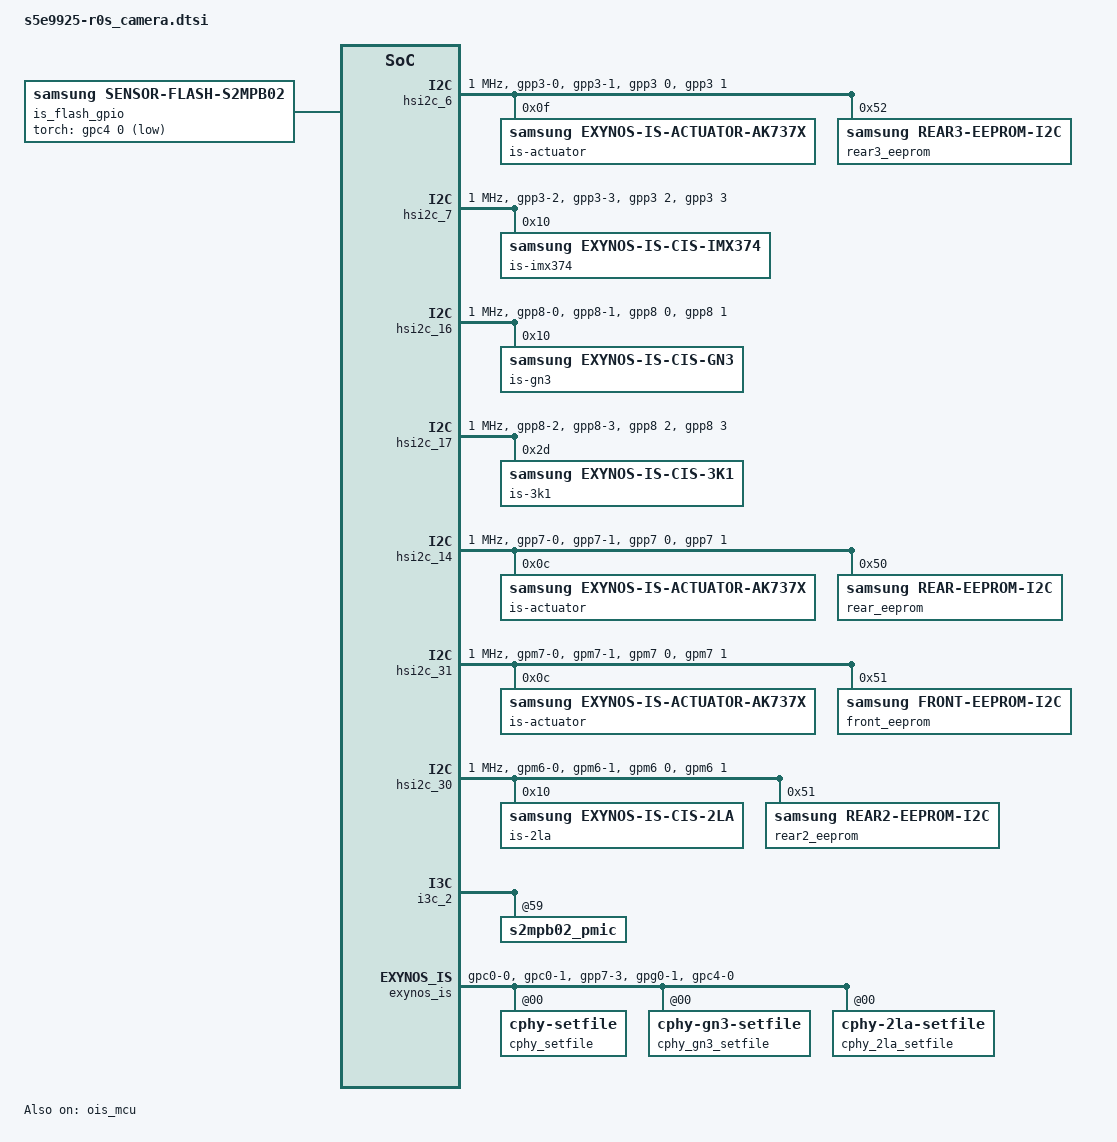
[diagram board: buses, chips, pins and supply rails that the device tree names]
/*
 * Samsung Exynos SoC series Pablo driver
 *
 * Copyright (c) 2020 Samsung Electronics Co., Ltd
 *
 * This program is free software; you can redistribute it and/or modify
 * it under the terms of the GNU General Public License version 2 as
 * published by the Free Software Foundation.
 */

#include <dt-bindings/camera/exynos_is_dt.h>

#include "module_gn3.dtsi"
#include "module_2la.dtsi"
#include "module_3k1.dtsi"
#include "module_imx374.dtsi"

/ {
	fragment@camera {
		target-path = "/";
		__overlay__ {
			#address-cells = <2>;
			#size-cells = <1>;
			interrupt-parent = <&gic>;

			is_flash_gpio: is-flash-gpio@0 {
				compatible = "samsung,sensor-flash-s2mpb02";
				sensor-module = <&is_sensor_gn3>, <&is_sensor_3k1>;
				id = <0 2>;
				status = "okay";

				torch-gpio = <&gpc4 0 0x1>;
			};

			/* OIS_MCU */
			ois_mcu: ois_mcu@173F0000 {
				pinctrl-names = "default";
				pinctrl-0 = <&ois_spi0 &ois_spi1>;
				compatible = "samsung,sensor-ois-mcu";
				reg = <0x0 0x173F0000 0x10000>, /* OIS MCU (SRAM 56KB) */
					<0x0 0x11DD0000 0x10000>, /* I2C: USI05_USI */
					<0x0 0x11DE0000 0x10000>,	/* SPI: USI06_USI */
					<0x0 0x11C30000 0x1000>;	/* PERI setting */
				reg-names = "core", "i2c", "spi", "peri";
				interrupts = <0 INTREQ__OIS_MCU_CSIS IRQ_TYPE_LEVEL_HIGH>;
				id = <0 2>;
				status = "okay";
				mcu_ctrl_actuator = <0 1>;
				mcu_support_photo_fastae;

				power-domains = <&pd_allcsis>;
				clocks = <&clock GATE_OIS_MCU_TOP_QCH>, <&clock DOUT_DIV_CLK_PERIC2_USI06>;
				clock-names = "user_mux", "ipclk_spi";
			};

			/* REAR CAMERA */
			is_sensor0: is_sensor0@17030000 {
				#address-cells = <1>;
				#size-cells = <1>;
				reg = <0x0 0x17050000 0x1000>, /* MIPI-CSI2 */
					<0x0 0x170F0000 0x10000>, /* PHY: M0S4S4S4S4S4S2 */
					<0x0 0x17150050 0x10>; /* CSIS_FRO */
				scenario = <SENSOR_SCENARIO_NORMAL>;	/* Normal, Vision, OIS etc */
				id = <0>;
				csi_ch = <2>;
				status = "okay";
				use_cphy = <1>;

				interrupts = <0 INTREQ__CSIS2 IRQ_TYPE_LEVEL_HIGH>;
				phys = <&mipi_phy_csis2_m0s4s4s4s4s4s4_s22 0>;
				phy_setfile = <&cphy_gn3_setfile>;
				phy_tune_default_mode = "4080 3060 60";
			};

			/* FRONT CAMERA */
			is_sensor1: is_sensor1@17040000 {
				#address-cells = <1>;
				#size-cells = <1>;
				reg = <0x0 0x17030000 0x1000>, /* MIPI-CSI0 */
					<0x0 0x170F0000 0x10000>, /* PHY: M0S4S4S4S4S4S2 */
					<0x0 0x17150050 0x10>; /* CSIS_FRO */
				scenario = <SENSOR_SCENARIO_NORMAL>;    /* Normal, Vision, OIS etc */
				id = <1>;
				csi_ch = <0>;
				status = "okay";
				use_cphy = <0>;

				interrupts = <0 INTREQ__CSIS0 IRQ_TYPE_LEVEL_HIGH>;
				phys = <&mipi_phy_csis0_m0s4s4s4s4s4s4_s22 0>;
			};

			/* Tele CAMERA */
			is_sensor2: is_sensor2@17050000 {
				#address-cells = <1>;
				#size-cells = <1>;
				reg = <0x0 0x17060000 0x1000>, /* MIPI-CSI3 */
					<0x0 0x170F0000 0x10000>, /* PHY: M0S4S4S4S4S4S2 */
					<0x0 0x17150050 0x10>; /* CSIS_FRO */
				scenario = <SENSOR_SCENARIO_NORMAL>;    /* Normal, Vision, OIS etc */
				id = <2>;
				csi_ch = <3>;
				status = "okay";
				use_cphy = <0>;

				interrupts = <0 INTREQ__CSIS3 IRQ_TYPE_LEVEL_HIGH>;
				phys = <&mipi_phy_csis3_m0s4s4s4s4s4s4_s22 0>;
			};

			is_sensor3: is_sensor3@17060000 {
				#address-cells = <1>;
				#size-cells = <1>;
				scenario = <SENSOR_SCENARIO_VISION>;    /* Normal, Vision, OIS etc */
				id = <3>;
				csi_ch = <4>;
				status = "okay";
			};

			/* ULTRA WIDE CAMERA */
			is_sensor4: is_sensor4@17070000 {
				#address-cells = <1>;
				#size-cells = <1>;
				reg = <0x0 0x17040000 0x1000>, /* MIPI-CSI1 */
					<0x0 0x170F0000 0x10000>, /* PHY: M0S4S4S4S4S4S2 */
					<0x0 0x17150050 0x10>; /* CSIS_FRO */
				scenario = <SENSOR_SCENARIO_NORMAL>;    /* Normal, Vision, OIS etc */
				id = <4>;
				csi_ch = <1>;
				status = "okay";
				use_cphy = <1>;

				interrupts = <0 INTREQ__CSIS1 IRQ_TYPE_LEVEL_HIGH>;
				phys = <&mipi_phy_csis1_m0s4s4s4s4s4s4_s22 0>;
				phy_setfile = <&cphy_2la_setfile>;
				phy_tune_default_mode = "2016 1134 120";
			};

			is_sensor5: is_sensor5@17080000 {
				#address-cells = <1>;
				#size-cells = <1>;
				scenario = <SENSOR_SCENARIO_NORMAL>;    /* Normal, Vision, OIS etc */
				id = <1>;
				csi_ch = <1>;
				status = "disabled";
			};
		}; /* end of __overlay__ */
	}; /* end of fragment */
}; /* end of root */

/***** reference symbol node *****/
&pinctrl_5 {
	wide_rst_sleep: wide-rst-sleep {
		samsung,pins = "gpc0-0";
		samsung,pin-con-pdn = <0>;
	};

	uwide_rst_sleep: uwide-rst-sleep {
		samsung,pins = "gpc0-1";
		samsung,pin-con-pdn = <0>;
	};
};

&pinctrl_6 {
	/* REAR WIDE */
	hsi2c16_bus_in: hsi2c16-bus-in {
		samsung,pins = "gpp8-0", "gpp8-1";
		samsung,pin-function = <0>;
		samsung,pin-pud = <0>;
		samsung,pin-drv = <0>;
		samsung,pin-pud-pdn = <0>;
	};

	/* REAR WIDE AF */
	hsi2c14_bus_in: hsi2c14-bus-in {
		samsung,pins = "gpp7-0", "gpp7-1";
		samsung,pin-function = <0>;
		samsung,pin-pud = <0>;
		samsung,pin-drv = <0>;
		samsung,pin-pud-pdn = <0>;
	};

	/* REAR TELE */
	hsi2c17_bus_in: hsi2c17-bus-in {
		samsung,pins = "gpp8-2", "gpp8-3";
		samsung,pin-function = <0>;
		samsung,pin-pud = <0>;
		samsung,pin-drv = <0>;
		samsung,pin-pud-pdn = <0>;
	};

	/* TELE RST */
	tele_rst_sleep: tele-rst-sleep {
		samsung,pins = "gpp7-3";
		samsung,pin-con-pdn = <0>;
	};
};

&pinctrl_7 {
	/* Tele AF */
	hsi2c6_bus_in: hsi2c6-bus-in {
		samsung,pins = "gpp3-0", "gpp3-1";
		samsung,pin-function = <0>;
		samsung,pin-pud = <0>;
		samsung,pin-drv = <0>;
		samsung,pin-pud-pdn = <0>;
	};

	/* Front */
	hsi2c7_bus_in: hsi2c7-bus-in {
		samsung,pins = "gpp3-2", "gpp3-3";
		samsung,pin-function = <0>;
		samsung,pin-pud = <0>;
		samsung,pin-drv = <0>;
		samsung,pin-pud-pdn = <0>;
	};

	/* Front RST */
	vt_rst_sleep: vt-rst-sleep {
		samsung,pins = "gpg0-1";
		samsung,pin-con-pdn = <0>;
	};

	/* torch */
	torch_sleep: torch-sleep {
		samsung,pins = "gpc4-0";
		samsung,pin-con-pdn= <3>;
	};

	/* ois spi 0*/
	ois_spi0: ois-spi0 {
		samsung,pins = "gpp6-0", "gpp6-1";
		samsung,pin-function = <0>;
		samsung,pin-pud = <1>;
	};

	/* ois spi 1*/
	ois_spi1: ois-spi1 {
		samsung,pins = "gpp6-2", "gpp6-3";
		samsung,pin-function = <0>;
		samsung,pin-pud = <0>;
		samsung,pin-con-pdn = <2>;
		samsung,pin-pud-pdn = <0>;
	};
};

&pinctrl_1 {
	/* Ultra Wide */
	hsi2c30_bus_in: hsi2c30-bus-in {
		samsung,pins = "gpm6-0", "gpm6-1";
		samsung,pin-function = <0>;
		samsung,pin-pud = <0>;
		samsung,pin-drv = <0>;
	};

	/* Front AF */
	hsi2c31_bus_in: hsi2c31-bus-in {
		samsung,pins = "gpm7-0", "gpm7-1";
		samsung,pin-function = <0>;
		samsung,pin-pud = <0>;
		samsung,pin-drv = <0>;
		samsung,pin-pud-pdn = <0>;
	};

	hsi2c31_bus: hsi2c31-bus {
		samsung,pin-drv = <3>;
	};
};

&hsi2c_6 {
	#address-cells = <1>;
	#size-cells = <0>;
	gpios = <&gpp3 0 0 &gpp3 1 0>;
	status = "okay";
	clock-frequency = <1000000>;
	samsung,reset-before-trans;
	samsung,fast-plus-mode;

	pinctrl-names = "default","on_i2c","off_i2c";
	pinctrl-0 = <&hsi2c6_bus_in>;
	pinctrl-1 = <&hsi2c6_bus>;
	pinctrl-2 = <&hsi2c6_bus_in>;

	is-actuator@0F { /* tele AF */
		compatible = "samsung,exynos-is-actuator-ak737x";
		sensor-module = <&is_sensor_3k1>;
		reg = <0x0F>;
		id = <2>; /* matching is_sensor id */
		/* AK737x: addr 0xF3, data 0x0E */
		vendor_product_id = <0xF3 0x0E 0xF3 0x13 0xF3 0x00>;
		vendor_first_pos = <2000>;  /* 12bits */
		vendor_first_delay = <2000>;
		vendor_soft_landing_seqid = <2>;
		vendor_soft_landing_list = <640 30 64 30>; /* 1st_pos delay 2nd_pos delay */  /* 12bits */
		vendor_use_sleep_mode;
		vendor_use_standby_mode; /* AK7377 with vendor_use_sleep_mode */
	};

	rear3_eeprom@52 { /* tele x3 */
		compatible = "samsung,rear3-eeprom-i2c";
		reg = <0x52>;

		rom_power_position = <2>;
		rom_size = <0x4000>;
		cal_map_es_version = <23>;
		camera_module_es_version = "A";
		/* skip_cal_loading; */

		/* Rainbow_project_R0G0_Rear_Cal_Map_V023_20210520_for_all */
		/* 0 header */
		header_crc_check_list = <0x0000 0x01FB 0x01FC>;
		/* 0 LSI Wide LSC data */
		/* 1 Tele camera */
		/* 2 ATC data */
		crc_check_list = <0x0200 0x15FB 0x15FC
						0x1D00 0x2D2B 0x2D2C
						0x2D30 0x2D5B 0x2D5C
						0x2D60 0x2D9B 0x2D9C
						0x2DA0 0x2E0B 0x2E0C
						0x2E10 0x361B 0x361C
						0x3620 0x367B 0x367C
						0x1D00 0x36DF 0x36FC
						0x3700 0x37FB 0x37FC>;

		/* Master */
		rom_header_version_start_addr = <0x40>;
		rom_header_cal_data_start_addr = <0x200>;
		rom_header_cal_map_ver_start_addr = <0x70>;
		rom_header_isp_setfile_ver_start_addr = <0x74>;
		rom_header_project_name_start_addr = <0x7E>;
		rom_header_module_id_addr = <0xAE>; /* 0xA8 + reserved bytes */
		rom_header_sensor_id_addr = <0xC8>;
		rom_header_mtf_data_addr = <0x182>;
		rom_awb_master_addr = <0x2D60>;
		rom_awb_module_addr = <0x2D84>;
		/* Near Far Mid1 ... Mid7 */
		rom_af_cal_addr = <0x2D40 0x2D34 0x2D38 0x2D3C>;

		/* Dual cal slave 0 - Tele */
		rom_dualcal_slave0_start_addr = <0x2E10>;
		rom_dualcal_slave0_size = <0x080C>; /* 2060 */
		/* x y z sx sy */
		/* range max_err avg_err dll_version prj_name */
		rom_dualcal_slave1_tilt_list = <0x2EC8 0x2ECC 0x2ED0 0x2EEC 0x2EF0
						0x30E2 0x30E6 0x30EA 0x3104 0x30EF>;

		/* sensor ois - xgg ygg xcoef ycoef xsupper ysupper calmark */
		/* sensor2 ois - xgg ygg xcoef ycoef xsupper ysupper calmark */
		/* TO DO */
		rom_ois_list = <0x2E20 0x2E24 0x2E2C 0x2E2E 0x2E48 0x2E4A 0x2E40
				0x3630 0x3634 0x363C 0x363E 0x3658 0x365A 0x3650>;
	};
};

&hsi2c_7 {
	#address-cells = <1>;
	#size-cells = <0>;
	gpios = <&gpp3 2 0 &gpp3 3 0>;
	status = "okay";
	clock-frequency = <1000000>;
	samsung,reset-before-trans;
	samsung,fast-plus-mode;

	pinctrl-names = "default","on_i2c","off_i2c";
	pinctrl-0 = <&hsi2c7_bus_in>;
	pinctrl-1 = <&hsi2c7_bus>;
	pinctrl-2 = <&hsi2c7_bus_in>;

	is-imx374@10 {
		compatible = "samsung,exynos-is-cis-imx374";
		sensor-module = <&is_sensor_imx374>;
		reg = <0x10>; /* 1 bit right shift */
		id = <1>; /* matching is_sensor id */
		setfile = "default";
		rev_reg = <0x0A1E 1 0x40>;
		vendor_use_adaptive_mipi;
	};
};

&hsi2c_16 {
	#address-cells = <1>;
	#size-cells = <0>;
	gpios = <&gpp8 0 0 &gpp8 1 0>;
	status = "okay";
	clock-frequency = <1000000>;
	samsung,reset-before-trans;
	samsung,fast-plus-mode;

	pinctrl-names = "default","on_i2c","off_i2c";
	pinctrl-0 = <&hsi2c16_bus_in>;
	pinctrl-1 = <&hsi2c16_bus>;
	pinctrl-2 = <&hsi2c16_bus_in>;

	is-gn3@10 {
		compatible = "samsung,exynos-is-cis-gn3";
		sensor-module = <&is_sensor_gn3>;
		reg = <0x10>; /* 1 bit right shift */
		id = <0>; /* matching is_sensor id */
		setfile = "default";
		rev_reg = <0x0002 2 0xA301>;
		vendor_use_adaptive_mipi;
	};
};

&hsi2c_17 {
	#address-cells = <1>;
	#size-cells = <0>;
	gpios = <&gpp8 2 0 &gpp8 3 0>;
	status = "okay";
	clock-frequency = <1000000>;
	samsung,reset-before-trans;
	samsung,fast-plus-mode;

	pinctrl-names = "default","on_i2c","off_i2c";
	pinctrl-0 = <&hsi2c17_bus_in>;
	pinctrl-1 = <&hsi2c17_bus>;
	pinctrl-2 = <&hsi2c17_bus_in>;

	is-3k1@2D {
		compatible = "samsung,exynos-is-cis-3k1";
		sensor-module = <&is_sensor_3k1>;
		reg = <0x2D>; /* 1 bit right shift */
		id = <2>; /* matching is_sensor id */
		setfile = "setA";
		rev_reg = <0x0002 2 0xA000>;
		vendor_use_adaptive_mipi;
	};
};

&hsi2c_14 {
	#address-cells = <1>;
	#size-cells = <0>;
	gpios = <&gpp7 0 0 &gpp7 1 0>;
	status = "okay";
	clock-frequency = <1000000>;
	samsung,reset-before-trans;
	samsung,fast-plus-mode;

	pinctrl-names = "default","on_i2c","off_i2c";
	pinctrl-0 = <&hsi2c14_bus_in>;
	pinctrl-1 = <&hsi2c14_bus>;
	pinctrl-2 = <&hsi2c14_bus_in>;

	is-actuator@0C { /* wide AF */
		compatible = "samsung,exynos-is-actuator-ak737x";
		sensor-module = <&is_sensor_gn3>;
		reg = <0x0C>;
		id = <0>; /* matching is_sensor id */
		/* AK737x: addr 0xF3, data 0x0E */
		vendor_product_id = <0xF3 0x0E 0xF3 0x13 0xF3 0x00>;
		vendor_first_pos = <2000>;  /* 12bits */
		vendor_first_delay = <2000>;
		vendor_soft_landing_seqid = <2>;
		vendor_soft_landing_list = <640 30 64 30>; /* 1st_pos delay 2nd_pos delay */  /* 12bits */
		vendor_use_sleep_mode;
		vendor_use_standby_mode; /* AK7377 with vendor_use_sleep_mode */
	};

	rear_eeprom@50 {
		compatible = "samsung,rear-eeprom-i2c";
		reg = <0x50>;
		rom_power_position = <0>;
		rom_size = <0x8000>;
		cal_map_es_version = <23>;
		camera_module_es_version = "A";
		/* skip_cal_loading; */

		/* Rainbow_project_R0G0_Rear_Cal_Map_V023_20210520_for_all */
		/* 0 header */
		header_crc_check_list = <0x0000 0x01FB 0x01FC>;
		/* 0 LSI Wide LSC data */
		/* 1 Wide camera */
		/* 2 ATC data */
		/* 3 Tele camera */
		/* 4 Sensor */
		crc_check_list = <0x0200 0x15FB 0x15FC
						0x1D00 0x2D2B 0x2D2C
						0x2D30 0x2D5B 0x2D5C
						0x2D60 0x2D9B 0x2D9C
						0x2DA0 0x2E0B 0x2E0C
						0x2E10 0x2E6B 0x2E6C
						0x2E70 0x2E9B 0x2E9C
						0x1D00 0x2EDF 0x2EFC
						0x2F00 0x2FFB 0x2FFC
						0x3000 0x4499 0x449A
						0x3000 0x44DF 0x44FC>;

		/* Master */
		rom_header_version_start_addr = <0x50>;
		rom_header_cal_data_start_addr = <0x200>;
		rom_header_cal_map_ver_start_addr = <0x70>;
		rom_header_isp_setfile_ver_start_addr = <0x74>;
		rom_header_project_name_start_addr = <0x7E>;
		rom_header_module_id_addr = <0xAE>; /* 0xA8 + reserved bytes */
		rom_header_sensor_id_addr = <0xB8>;
		rom_header_mtf_data_addr = <0xE0>;
		rom_paf_cal_start_addr = <0x1D00>;
		rom_awb_master_addr = <0x2D60>;
		rom_awb_module_addr = <0x2D84>;
		/* Near Far Mid1 ... Mid7 */
		rom_af_cal_addr = <0x2D40 0x2D34 0x2D38 0x2D3C>;

		/* rom_xtc_cal_endian_check; */
		rom_xtc_cal_data_addr_list = <0x3000 0x4499 0x1>;

 		/* sensor ois - xgg ygg xcoef ycoef xsupper ysupper calmark */
		/* sensor2 ois - xgg ygg xcoef ycoef xsupper ysupper calmark */
		/* TO DO */
		rom_ois_list = <0x2E20 0x2E24 0x2E2C 0x2E2E 0x2E48 0x2E4A 0x2E40
				0x3630 0x3634 0x363C 0x363E 0x3658 0x365A 0x3650>;
	};
};

&hsi2c_31 {
	#address-cells = <1>;
	#size-cells = <0>;
	gpios = <&gpm7 0 0 &gpm7 1 0>;
	status = "okay";
	clock-frequency = <1000000>;
	samsung,reset-before-trans;
	samsung,fast-plus-mode;

	pinctrl-names = "default","on_i2c","off_i2c";
	pinctrl-0 = <&hsi2c31_bus_in>;
	pinctrl-1 = <&hsi2c31_bus>;
	pinctrl-2 = <&hsi2c31_bus_in>;

	is-actuator@0C { /* front AF */
		compatible = "samsung,exynos-is-actuator-ak737x";
		sensor-module = <&is_sensor_imx374>;
		reg = <0x0C>;
		id = <1>; /* matching is_sensor id */
		/* AK737x: addr 0xF3, data 0x0E */
		vendor_product_id = <0xF3 0x0E>;
		vendor_first_pos = <960>;  /* 12bits */
		vendor_first_delay = <2000>;
	};

	front_eeprom@51 {
		compatible = "samsung,front-eeprom-i2c";
		reg = <0x51>;
		rom_power_position = <1>;
		rom_size = <0x4000>;
		cal_map_es_version = <23>;
		camera_module_es_version = "A";
		/*skip_cal_loading;*/
		/* Rainbow_project_R0G0_Front_Cal_Map_V023_20210520_for_all */
		/* 0 header */
		header_crc_check_list = <0x0000 0x015F 0x01FC>;
		/* 0 master */
		crc_check_list = <0x0200 0x1BFB 0x1BFC
			0x2300 0x32FF 0x3300
			0x330C 0x3337 0x3338
			0x333C 0x3367 0x3368
			0x2300 0x33DF 0x33FC>;
		/* Master */
		rom_header_version_start_addr = <0x30>;
		rom_header_cal_data_start_addr = <0x200>;
		rom_header_cal_map_ver_start_addr = <0x50>;
		/* rom_header_isp_setfile_ver_start_addr = <>; */
		rom_header_project_name_start_addr = <0x5C>;
		rom_header_module_id_addr = <0xAE>; /* 0xA8 + reserved bytes */
		rom_header_sensor_id_addr = <0x70>;
		rom_header_mtf_data_addr = <0xE0>;
		rom_paf_cal_start_addr = <0x2300>;
		rom_awb_master_addr = <0x333C>;
		rom_awb_module_addr = <0x3348>;
		/* Near Far Mid1 ... Mid7 */
		rom_af_cal_addr = <0x331C 0x3310>;
	};
};

&hsi2c_30 {
	#address-cells = <1>;
	#size-cells = <0>;
	gpios = <&gpm6 0 0 &gpm6 1 0>;
	status = "okay";
	clock-frequency = <1000000>;
	samsung,reset-before-trans;
	samsung,fast-plus-mode;

	pinctrl-names = "default","on_i2c","off_i2c";
	pinctrl-0 = <&hsi2c30_bus_in>;
	pinctrl-1 = <&hsi2c30_bus>;
	pinctrl-2 = <&hsi2c30_bus_in>;

	is-2la@10 { /* ultrawide */
		compatible = "samsung,exynos-is-cis-2la";
		sensor-module = <&is_sensor_2la>;
		reg = <0x10>; /* 1 bit right shift */
		id = <4>; /* matching fimc_is_sensor id */
		setfile = "setA";
		status = "okay";
		rev_reg = <0x0002 2 0xA202>;
		vendor_use_adaptive_mipi;
	};

	rear2_eeprom@51 { /* Ultra wide eeprom */
		compatible = "samsung,rear2-eeprom-i2c";
		reg = <0x51>;

		rom_power_position = <4>;
		rom_size = <0x4000>;
		cal_map_es_version = <23>;
		camera_module_es_version = "A";
		/* skip_cal_loading; */

		/* Rainbow_project_R0G0_Rear_Cal_Map_V023_20210520_for_all */
		/* 0 header */
		header_crc_check_list = <0x0000 0x00FB 0x00FC>;
		/* 0 master LSC */
		/* 1 master all */
		crc_check_list = <0x0100 0x14FB 0x14FC
			0x2C60 0x2C9B 0x2C9C
			0x2CA0 0x2D0B 0x2D0C
			0x1C00 0x2DDF 0x2DFC>;
		/* Master */
		rom_header_version_start_addr = <0x40>;
		rom_header_cal_data_start_addr = <0x100>;
		rom_header_cal_map_ver_start_addr = <0x50>;
		rom_header_isp_setfile_ver_start_addr = <0x54>;
		rom_header_project_name_start_addr = <0x5E>;
		rom_header_module_id_addr = <0xAE>; /* 0xA8 + reserved bytes */
		rom_header_sensor_id_addr = <0xB8>;
		rom_header_mtf_data_addr = <0x66>;
		rom_awb_master_addr = <0x2C60>;
		rom_awb_module_addr = <0x2C84>;
	};
};

&i3c_2 {
	s2mpb02_pmic@59 {
		torch {
			torch1-gpio = <&gpc4 0 0x1>;

			status = "okay";

			leds1 {
				ledname = "leds-sec1";
				id = <0>;
				brightness = <0xE>; /* adaptive Nx100+50 : 1450mA */
				timeout = <0x7>; /* (N+1)x62.5 : 500ms */
				torch_table_enable = <0>;
			};

			leds2 {
				ledname = "torch-sec1";
				id = <1>;
				brightness = <0xE>; /* Nx20 = 280mA */
				timeout = <0xF>;
				torch_table_enable = <1>;
				torch_table = <3 5 5 6 6 8 8 8 10 10>;
				/* 60mA 100mA 120mA 160mA 200mA */
			};
		};
	};
};

&exynos_is {
	phy_ldos = "AVDD_CSI_0P85", "AVDD_CSI_1P2";

	pinctrl-names = "default";
	pinctrl-0 = <&wide_rst_sleep &uwide_rst_sleep &tele_rst_sleep &vt_rst_sleep &torch_sleep>;

	secure_mem_info = <0x96000000 0x36F0000>;

	vender {
		use_module_check;
		use_ois;
		check_sensor_vendor;
		ois_sensor_index = <0>;
		aperture_sensor_index = <0>;
		mcu_sensor_index = <0>;

		is_vendor_sensor_count = <5>;
		max_supported_camera = <6>;
		supported_cameraId = <56 58 52 1 21 23>;
		ois_gyro_list = <0x00 0x00 0x10 0x00 0x00>;
		/*
		* Wide(0)
		* Front(1)
		* U Wide(2)
		* Front 80(3) - not available for factory
		* Rear ToF(4) - not available for factory
		* Front Secure(5) - not available for factory
		* Dual Zoom(20)
		* Dual Portrait Tele(21) - Main Tele/Sub Wide
		* Dual Portrait Wide(23) - Main Wide/Sub U Wide
		* Tele 2x2(50)
		* Tele 17.9(52)
		* Front_3(53)
		* Tele_2(54)
		* Front_4(55)
		* Rear_Wide(56)
		* Rear_UW(58)
		* REAR ToF(80)
		*/

		/* sysfs camera id */
		max_camera_num = <9>;
		sensor_id { /* sensor position = <sensor_id> */
			0 = <71>;	/* GN3 */
			1 = <126>;	/* IMX374 */
			2 = <70>;	/* 3K1 */
			4 = <53>;	/* 2LA */
		};
		camera_info0 {			/* 0 : sysfs rear */
			internal_id = <0>;	/* 0 : wide */
			isp = <0>;		/* 0 : INT, 1 : EXT, 2 : SOC */
			cal_memory = <2>;	/* 0 : N, 1 : FROM, 2 : EEPROM, 3 : OTP */
			read_version = <0>;	/* 0 : SYSFS, 1 : CAMON */
			core_voltage = <0>;	/* 0 : N, 1 : Y */
			upgrade = <0>;		/* 0 : N, 1 : SYSFS , 2 : CAMON */
			fw_write = <0>;		/* 0 : N, 1 : OS, 2 : SD, 3 : ALL */
			fw_dump = <0>;		/* 0 : N, 1 : Y */
			companion = <0>;	/* 0 : N, 1 : Y */
			ois = <1>;		/* 0 : N, 1 : Y */
			valid = <1>;		/* 0 : INVALID, 1 : VALID */
		};
		camera_info1 {			/* 1 : sysfs front */
			internal_id = <1>;	/* 1 : front master */
			isp = <0>;		/* 0 : INT, 1 : EXT, 2 : SOC */
			cal_memory = <2>;	/* 0 : N, 1 : FROM, 2 : EEPROM, 3 : OTP */
			read_version = <0>;	/* 0 : SYSFS, 1 : CAMON */
			core_voltage = <0>;	/* 0 : N, 1 : Y */
			upgrade = <0>;		/* 0 : N, 1 : SYSFS, 2 : CAMON */
			fw_write = <0>;		/* 0 : N, 1 : OS, 2 : SD, 3 : ALL */
			fw_dump = <0>;		/* 0 : N, 1 : Y */
			companion = <0>;	/* 0 : N, 1 : Y */
			ois = <0>;		/* 0 : N, 1 : Y */
			valid = <1>;		/* 0 : INVALID, 1 : VALID */
		};
		camera_info2 {			/* 2 : sysfs rear2 */
			internal_id = <4>;	/* 4 : ultra wide */
			isp = <0>;		/* 0 : INT, 1 : EXT, 2 : SOC */
			cal_memory = <2>;	/* 0 : N, 1 : FROM, 2 : EEPROM, 3 : OTP */
			read_version = <0>;	/* 0 : SYSFS, 1 : CAMON */
			core_voltage = <0>;	/* 0 : N, 1 : Y */
			upgrade = <0>;		/* 0 : N, 1 : SYSFS, 2 : CAMON */
			fw_write = <0>;		/* 0 : N, 1 : OS, 2 : SD, 3 : ALL */
			fw_dump = <0>;		/* 0 : N, 1 : Y */
			companion = <0>;	/* 0 : N, 1 : Y */
			ois = <0>;		/* 0 : N, 1 : Y */
			valid = <1>;		/* 0 : INVALID, 1 : VALID */
		};
		camera_info3 {			/* 3 : sysfs front2 */
			internal_id = <3>;	/* 3 : front sub */
			isp = <0>;		/* 0 : INT, 1 : EXT, 2 : SOC */
			cal_memory = <2>;	/* 0 : N, 1 : FROM, 2 : EEPROM, 3 : OTP */
			read_version = <0>;	/* 0 : SYSFS, 1 : CAMON */
			core_voltage = <0>;	/* 0 : N, 1 : Y */
			upgrade = <0>;		/* 0 : N, 1 : SYSFS, 2 : CAMON */
			fw_write = <0>;		/* 0 : N, 1 : OS, 2 : SD, 3 : ALL */
			fw_dump = <0>;		/* 0 : N, 1 : Y */
			companion = <0>;	/* 0 : N, 1 : Y */
			ois = <0>;		/* 0 : N, 1 : Y */
			valid = <1>;		/* 0 : INVALID, 1 : VALID */
		};
		camera_info4 {			/* 4 : sysfs rear3 */
			internal_id = <2>;	/* 4 : tele */
			isp = <0>;		/* 0 : INT, 1 : EXT, 2 : SOC */
			cal_memory = <2>;	/* 0 : N, 1 : FROM, 2 : EEPROM, 3 : OTP */
			read_version = <0>;	/* 0 : SYSFS, 1 : CAMON */
			core_voltage = <0>;	/* 0 : N, 1 : Y */
			upgrade = <0>;		/* 0 : N, 1 : SYSFS, 2 : CAMON */
			fw_write = <0>;		/* 0 : N, 1 : OS, 2 : SD, 3 : ALL */
			fw_dump = <0>;		/* 0 : N, 1 : Y */
			companion = <0>;	/* 0 : N, 1 : Y */
			ois = <1>;		/* 0 : N, 1 : Y */
			valid = <1>;		/* 0 : INVALID, 1 : VALID   */
		};
		camera_info5 {			/* 5 : sysfs front3 */
			valid = <0>;		/* 0 : INVALID, 1 : VALID */
		};
		camera_info6 {			/* 6 : sysfs rear4 */
			valid = <0>;		/* 0 : INVALID, 1 : VALID */
		};
		camera_info7 {			/* 7 : sysfs front4 */
			valid = <0>;		/* 0 : INVALID, 1 : VALID */
		};
		camera_info8 {			/* 8 : sysfs rear tof */
			internal_id = <8>;	/* 3 : rear tof */
			isp = <0>;		/* 0 : INT, 1 : EXT, 2 : SOC */
			cal_memory = <2>;	/* 0 : N, 1 : FROM, 2 : EEPROM, 3 : OTP  */
			read_version = <0>;	/* 0 : SYSFS, 1 : CAMON */
			core_voltage = <0>;	/* 0 : N, 1 : Y */
			upgrade = <0>;		/* 0 : N, 1 : SYSFS, 2 : CAMON */
			fw_write = <0>;		/* 0 : N, 1 : OS, 2 : SD, 3 : ALL */
			fw_dump = <0>;		/* 0 : N, 1 : Y */
			companion = <0>;	/* 0 : N, 1 : Y */
			ois = <0>;		/* 0 : N, 1 : Y */
			valid = <1>;		/* 0 : INVALID, 1 : VALID */
		};
	};

	lic_offsets {
		/* 3AA = <setA lic offset0, setA lic offset1, set A trigger context */
		/*		setB lic offset0, setB lic offset1, set B trigger context> */
		/* 4672: 4640x4352 */
		/* 5824: 5804x4352 */
		3AA = <5461 10922 16383 0 5461 10922 16383 0>;
	};

	is_dvfs {
		#define CPU_CL0 "0-3"
		#define CPU_CL1 "4-6"
		#define CPU_CL2 "7"
		#define CPU_CL12 "4-7"

		table0 {
			desc = "dvfs table v0.2";

			default_int_cam = <1>;
			default_cam = <1>;
			default_csis = <1>;
			default_isp = <1>;
			default_mif = <1>;
			default_int = <1>;
			default_cpu = CPU_CL0;

			rear_single_wide_photo_int_cam = <6>;
			rear_single_wide_photo_cam = <6>;
			rear_single_wide_photo_csis = <5>;
			rear_single_wide_photo_isp = <6>;
			rear_single_wide_photo_mif = <6>;
			rear_single_wide_photo_int = <5>;
			rear_single_wide_photo_cpu = CPU_CL0;

			rear_single_wide_photo_full_int_cam = <6>;
			rear_single_wide_photo_full_cam = <6>;
			rear_single_wide_photo_full_csis = <5>;
			rear_single_wide_photo_full_isp = <6>;
			rear_single_wide_photo_full_mif = <3>;
			rear_single_wide_photo_full_int = <5>;
			rear_single_wide_photo_full_cpu = CPU_CL0;

			rear_single_wide_video_fhd30_int_cam = <6>;
			rear_single_wide_video_fhd30_cam = <7>;
			rear_single_wide_video_fhd30_csis = <5>;
			rear_single_wide_video_fhd30_isp = <7>;
			rear_single_wide_video_fhd30_mif = <8>;
			rear_single_wide_video_fhd30_int = <5>;
			rear_single_wide_video_fhd30_cpu = CPU_CL0;

			rear_single_wide_videohdr_int_cam = <6>;
			rear_single_wide_videohdr_cam = <6>;
			rear_single_wide_videohdr_csis = <5>;
			rear_single_wide_videohdr_isp = <7>;
			rear_single_wide_videohdr_mif = <8>;
			rear_single_wide_videohdr_int = <5>;
			rear_single_wide_videohdr_cpu = CPU_CL0;

			rear_single_wide_video_fhd60_int_cam = <6>;
			rear_single_wide_video_fhd60_cam = <6>;
			rear_single_wide_video_fhd60_csis = <5>;
			rear_single_wide_video_fhd60_isp = <6>;
			rear_single_wide_video_fhd60_mif = <7>;
			rear_single_wide_video_fhd60_int = <5>;
			rear_single_wide_video_fhd60_cpu = CPU_CL12;

			rear_single_wide_video_fhd60_hf_int_cam = <6>;
			rear_single_wide_video_fhd60_hf_cam = <6>;
			rear_single_wide_video_fhd60_hf_csis = <5>;
			rear_single_wide_video_fhd60_hf_isp = <6>;
			rear_single_wide_video_fhd60_hf_mif = <7>;
			rear_single_wide_video_fhd60_hf_int = <5>;
			rear_single_wide_video_fhd60_hf_cpu = CPU_CL12;

			rear_single_wide_video_fhd60_supersteady_int_cam = <5>;
			rear_single_wide_video_fhd60_supersteady_cam = <6>;
			rear_single_wide_video_fhd60_supersteady_csis = <5>;
			rear_single_wide_video_fhd60_supersteady_isp = <6>;
			rear_single_wide_video_fhd60_supersteady_mif = <7>;
			rear_single_wide_video_fhd60_supersteady_int = <5>;
			rear_single_wide_video_fhd60_supersteady_cpu = CPU_CL12;

			rear_single_wide_video_fhd60_hf_supersteady_int_cam = <5>;
			rear_single_wide_video_fhd60_hf_supersteady_cam = <6>;
			rear_single_wide_video_fhd60_hf_supersteady_csis = <5>;
			rear_single_wide_video_fhd60_hf_supersteady_isp = <6>;
			rear_single_wide_video_fhd60_hf_supersteady_mif = <7>;
			rear_single_wide_video_fhd60_hf_supersteady_int = <5>;
			rear_single_wide_video_fhd60_hf_supersteady_cpu = CPU_CL12;

			rear_single_wide_video_uhd30_int_cam = <6>;
			rear_single_wide_video_uhd30_cam = <6>;
			rear_single_wide_video_uhd30_csis = <5>;
			rear_single_wide_video_uhd30_isp = <7>;
			rear_single_wide_video_uhd30_mif = <7>;
			rear_single_wide_video_uhd30_int = <4>;
			rear_single_wide_video_uhd30_cpu = CPU_CL0;

			rear_single_wide_video_uhd60_int_cam = <5>;
			rear_single_wide_video_uhd60_cam = <5>;
			rear_single_wide_video_uhd60_csis = <5>;
			rear_single_wide_video_uhd60_isp = <6>;
			rear_single_wide_video_uhd60_mif = <5>;
			rear_single_wide_video_uhd60_int = <3>;
			rear_single_wide_video_uhd60_cpu = CPU_CL12;

			rear_single_wide_video_uhd60_hf_int_cam = <5>;
			rear_single_wide_video_uhd60_hf_cam = <5>;
			rear_single_wide_video_uhd60_hf_csis = <5>;
			rear_single_wide_video_uhd60_hf_isp = <7>;
			rear_single_wide_video_uhd60_hf_mif = <6>;
			rear_single_wide_video_uhd60_hf_int = <3>;
			rear_single_wide_video_uhd60_hf_cpu = CPU_CL12;

			rear_single_wide_video_uhd120_int_cam = <6>;
			rear_single_wide_video_uhd120_cam = <4>;
			rear_single_wide_video_uhd120_csis = <5>;
			rear_single_wide_video_uhd120_isp = <4>;
			rear_single_wide_video_uhd120_mif = <3>;
			rear_single_wide_video_uhd120_int = <2>;
			rear_single_wide_video_uhd120_cpu = CPU_CL12;

			rear_single_wide_capture_int_cam = <3>;
			rear_single_wide_capture_cam = <3>;
			rear_single_wide_capture_csis = <5>;
			rear_single_wide_capture_isp = <3>;
			rear_single_wide_capture_mif = <1>;
			rear_single_wide_capture_int = <5>;
			rear_single_wide_capture_cpu = CPU_CL0;

			rear_single_wide_remosaic_photo_int_cam = <1>;
			rear_single_wide_remosaic_photo_cam = <1>;
			rear_single_wide_remosaic_photo_csis = <1>;
			rear_single_wide_remosaic_photo_isp = <1>;
			rear_single_wide_remosaic_photo_mif = <1>;
			rear_single_wide_remosaic_photo_int = <1>;
			rear_single_wide_remosaic_photo_cpu = CPU_CL0;

			rear_single_wide_remosaic_capture_int_cam = <1>;
			rear_single_wide_remosaic_capture_cam = <1>;
			rear_single_wide_remosaic_capture_csis = <1>;
			rear_single_wide_remosaic_capture_isp = <1>;
			rear_single_wide_remosaic_capture_mif = <1>;
			rear_single_wide_remosaic_capture_int = <1>;
			rear_single_wide_remosaic_capture_cpu = CPU_CL0;

			rear_single_wide_video_fhd120_int_cam = <8>;
			rear_single_wide_video_fhd120_cam = <5>;
			rear_single_wide_video_fhd120_csis = <5>;
			rear_single_wide_video_fhd120_isp = <7>;
			rear_single_wide_video_fhd120_mif = <5>;
			rear_single_wide_video_fhd120_int = <4>;
			rear_single_wide_video_fhd120_cpu = CPU_CL12;

			rear_single_wide_video_fhd240_int_cam = <8>;
			rear_single_wide_video_fhd240_cam = <5>;
			rear_single_wide_video_fhd240_csis = <5>;
			rear_single_wide_video_fhd240_isp = <5>;
			rear_single_wide_video_fhd240_mif = <4>;
			rear_single_wide_video_fhd240_int = <3>;
			rear_single_wide_video_fhd240_cpu = CPU_CL12;

			rear_single_wide_video_fhd480_int_cam = <8>;
			rear_single_wide_video_fhd480_cam = <5>;
			rear_single_wide_video_fhd480_csis = <5>;
			rear_single_wide_video_fhd480_isp = <5>;
			rear_single_wide_video_fhd480_mif = <3>;
			rear_single_wide_video_fhd480_int = <2>;
			rear_single_wide_video_fhd480_cpu = CPU_CL12;

			rear_single_wide_ssm_int_cam = <8>;
			rear_single_wide_ssm_cam = <5>;
			rear_single_wide_ssm_csis = <4>;
			rear_single_wide_ssm_isp = <5>;
			rear_single_wide_ssm_mif = <3>;
			rear_single_wide_ssm_int = <2>;
			rear_single_wide_ssm_hpg = <6>;
			rear_single_wide_ssm_cpu = CPU_CL12;

			rear_single_wide_video_8k24_int_cam = <5>;
			rear_single_wide_video_8k24_cam = <5>;
			rear_single_wide_video_8k24_csis = <5>;
			rear_single_wide_video_8k24_isp = <5>;
			rear_single_wide_video_8k24_mif = <6>;
			rear_single_wide_video_8k24_int = <3>;
			rear_single_wide_video_8k24_cpu = CPU_CL0;

			rear_single_wide_video_8k24_hf_int_cam = <5>;
			rear_single_wide_video_8k24_hf_cam = <5>;
			rear_single_wide_video_8k24_hf_csis = <5>;
			rear_single_wide_video_8k24_hf_isp = <6>;
			rear_single_wide_video_8k24_hf_mif = <7>;
			rear_single_wide_video_8k24_hf_int = <3>;
			rear_single_wide_video_8k24_hf_cpu = CPU_CL0;

			rear_single_wide_video_8k30_int_cam = <4>;
			rear_single_wide_video_8k30_cam = <5>;
			rear_single_wide_video_8k30_csis = <5>;
			rear_single_wide_video_8k30_isp = <5>;
			rear_single_wide_video_8k30_mif = <4>;
			rear_single_wide_video_8k30_int = <2>;
			rear_single_wide_video_8k30_cpu = CPU_CL0;

			rear_single_wide_video_8k30_hf_int_cam = <4>;
			rear_single_wide_video_8k30_hf_cam = <5>;
			rear_single_wide_video_8k30_hf_csis = <5>;
			rear_single_wide_video_8k30_hf_isp = <6>;
			rear_single_wide_video_8k30_hf_mif = <5>;
			rear_single_wide_video_8k30_hf_int = <2>;
			rear_single_wide_video_8k30_hf_cpu = CPU_CL0;

			rear_single_wide_vt_int_cam = <6>;
			rear_single_wide_vt_cam = <7>;
			rear_single_wide_vt_csis = <5>;
			rear_single_wide_vt_isp = <7>;
			rear_single_wide_vt_mif = <8>;
			rear_single_wide_vt_int = <5>;
			rear_single_wide_vt_cpu = CPU_CL0;

			rear_single_ultrawide_photo_int_cam = <6>;
			rear_single_ultrawide_photo_cam = <6>;
			rear_single_ultrawide_photo_csis = <6>;
			rear_single_ultrawide_photo_isp = <6>;
			rear_single_ultrawide_photo_mif = <6>;
			rear_single_ultrawide_photo_int = <5>;
			rear_single_ultrawide_photo_cpu = CPU_CL0;

			rear_single_ultrawide_photo_full_int_cam = <6>;
			rear_single_ultrawide_photo_full_cam = <6>;
			rear_single_ultrawide_photo_full_csis = <6>;
			rear_single_ultrawide_photo_full_isp = <6>;
			rear_single_ultrawide_photo_full_mif = <3>;
			rear_single_ultrawide_photo_full_int = <5>;
			rear_single_ultrawide_photo_full_cpu = CPU_CL0;

			rear_single_ultrawide_video_fhd30_int_cam = <6>;
			rear_single_ultrawide_video_fhd30_cam = <7>;
			rear_single_ultrawide_video_fhd30_csis = <6>;
			rear_single_ultrawide_video_fhd30_isp = <7>;
			rear_single_ultrawide_video_fhd30_mif = <8>;
			rear_single_ultrawide_video_fhd30_int = <5>;
			rear_single_ultrawide_video_fhd30_cpu = CPU_CL0;

			rear_single_ultrawide_video_fhd30_supersteady_int_cam = <6>;
			rear_single_ultrawide_video_fhd30_supersteady_cam = <7>;
			rear_single_ultrawide_video_fhd30_supersteady_csis = <6>;
			rear_single_ultrawide_video_fhd30_supersteady_isp = <7>;
			rear_single_ultrawide_video_fhd30_supersteady_mif = <8>;
			rear_single_ultrawide_video_fhd30_supersteady_int = <5>;
			rear_single_ultrawide_video_fhd30_supersteady_cpu = CPU_CL0;

			rear_single_ultrawide_video_fhd30_hf_supersteady_int_cam = <6>;
			rear_single_ultrawide_video_fhd30_hf_supersteady_cam = <7>;
			rear_single_ultrawide_video_fhd30_hf_supersteady_csis = <6>;
			rear_single_ultrawide_video_fhd30_hf_supersteady_isp = <7>;
			rear_single_ultrawide_video_fhd30_hf_supersteady_mif = <8>;
			rear_single_ultrawide_video_fhd30_hf_supersteady_int = <5>;
			rear_single_ultrawide_video_fhd30_hf_supersteady_cpu = CPU_CL0;

			rear_single_ultrawide_video_fhd60_int_cam = <6>;
			rear_single_ultrawide_video_fhd60_cam = <6>;
			rear_single_ultrawide_video_fhd60_csis = <6>;
			rear_single_ultrawide_video_fhd60_isp = <6>;
			rear_single_ultrawide_video_fhd60_mif = <7>;
			rear_single_ultrawide_video_fhd60_int = <5>;
			rear_single_ultrawide_video_fhd60_cpu = CPU_CL12;

			rear_single_ultrawide_video_fhd60_supersteady_int_cam = <1>;
			rear_single_ultrawide_video_fhd60_supersteady_cam = <1>;
			rear_single_ultrawide_video_fhd60_supersteady_csis = <1>;
			rear_single_ultrawide_video_fhd60_supersteady_isp = <1>;
			rear_single_ultrawide_video_fhd60_supersteady_mif = <1>;
			rear_single_ultrawide_video_fhd60_supersteady_int = <1>;
			rear_single_ultrawide_video_fhd60_supersteady_cpu = CPU_CL12;

			rear_single_ultrawide_video_fhd60_hf_supersteady_int_cam = <1>;
			rear_single_ultrawide_video_fhd60_hf_supersteady_cam = <1>;
			rear_single_ultrawide_video_fhd60_hf_supersteady_csis = <1>;
			rear_single_ultrawide_video_fhd60_hf_supersteady_isp = <1>;
			rear_single_ultrawide_video_fhd60_hf_supersteady_mif = <1>;
			rear_single_ultrawide_video_fhd60_hf_supersteady_int = <1>;
			rear_single_ultrawide_video_fhd60_hf_supersteady_cpu = CPU_CL12;

			rear_single_ultrawide_video_uhd30_int_cam = <6>;
			rear_single_ultrawide_video_uhd30_cam = <6>;
			rear_single_ultrawide_video_uhd30_csis = <6>;
			rear_single_ultrawide_video_uhd30_isp = <7>;
			rear_single_ultrawide_video_uhd30_mif = <7>;
			rear_single_ultrawide_video_uhd30_int = <4>;
			rear_single_ultrawide_video_uhd30_cpu = CPU_CL0;

			rear_single_ultrawide_video_uhd60_int_cam = <5>;
			rear_single_ultrawide_video_uhd60_cam = <5>;
			rear_single_ultrawide_video_uhd60_csis = <6>;
			rear_single_ultrawide_video_uhd60_isp = <6>;
			rear_single_ultrawide_video_uhd60_mif = <5>;
			rear_single_ultrawide_video_uhd60_int = <3>;
			rear_single_ultrawide_video_uhd60_cpu = CPU_CL12;

			rear_single_ultrawide_ssm_int_cam = <1>;
			rear_single_ultrawide_ssm_cam = <1>;
			rear_single_ultrawide_ssm_csis = <1>;
			rear_single_ultrawide_ssm_isp = <1>;
			rear_single_ultrawide_ssm_mif = <1>;
			rear_single_ultrawide_ssm_int = <1>;
			rear_single_ultrawide_ssm_hpg = <6>;
			rear_single_ultrawide_ssm_cpu = CPU_CL12;

			rear_single_ultrawide_capture_int_cam = <3>;
			rear_single_ultrawide_capture_cam = <3>;
			rear_single_ultrawide_capture_csis = <6>;
			rear_single_ultrawide_capture_isp = <3>;
			rear_single_ultrawide_capture_mif = <1>;
			rear_single_ultrawide_capture_int = <5>;
			rear_single_ultrawide_capture_cpu = CPU_CL0;

			rear_single_ultrawide_video_fhd120_int_cam = <8>;
			rear_single_ultrawide_video_fhd120_cam = <5>;
			rear_single_ultrawide_video_fhd120_csis = <5>;
			rear_single_ultrawide_video_fhd120_isp = <7>;
			rear_single_ultrawide_video_fhd120_mif = <5>;
			rear_single_ultrawide_video_fhd120_int = <4>;
			rear_single_ultrawide_video_fhd120_cpu = CPU_CL12;

			rear_single_tele_photo_int_cam = <6>;
			rear_single_tele_photo_cam = <6>;
			rear_single_tele_photo_csis = <6>;
			rear_single_tele_photo_isp = <6>;
			rear_single_tele_photo_mif = <6>;
			rear_single_tele_photo_int = <5>;
			rear_single_tele_photo_cpu = CPU_CL0;

			rear_single_tele_photo_full_int_cam = <6>;
			rear_single_tele_photo_full_cam = <6>;
			rear_single_tele_photo_full_csis = <6>;
			rear_single_tele_photo_full_isp = <6>;
			rear_single_tele_photo_full_mif = <3>;
			rear_single_tele_photo_full_int = <5>;
			rear_single_tele_photo_full_cpu = CPU_CL0;

			rear_single_tele_video_fhd30_int_cam = <6>;
			rear_single_tele_video_fhd30_cam = <7>;
			rear_single_tele_video_fhd30_csis = <6>;
			rear_single_tele_video_fhd30_isp = <7>;
			rear_single_tele_video_fhd30_mif = <8>;
			rear_single_tele_video_fhd30_int = <5>;
			rear_single_tele_video_fhd30_cpu = CPU_CL0;

			rear_single_tele_video_uhd30_int_cam = <6>;
			rear_single_tele_video_uhd30_cam = <6>;
			rear_single_tele_video_uhd30_csis = <6>;
			rear_single_tele_video_uhd30_isp = <7>;
			rear_single_tele_video_uhd30_mif = <7>;
			rear_single_tele_video_uhd30_int = <4>;
			rear_single_tele_video_uhd30_cpu = CPU_CL0;

			rear_single_tele_video_fhd60_int_cam = <6>;
			rear_single_tele_video_fhd60_cam = <6>;
			rear_single_tele_video_fhd60_csis = <6>;
			rear_single_tele_video_fhd60_isp = <6>;
			rear_single_tele_video_fhd60_mif = <7>;
			rear_single_tele_video_fhd60_int = <5>;
			rear_single_tele_video_fhd60_cpu = CPU_CL12;

			rear_single_tele_video_uhd60_int_cam = <5>;
			rear_single_tele_video_uhd60_cam = <5>;
			rear_single_tele_video_uhd60_csis = <6>;
			rear_single_tele_video_uhd60_isp = <6>;
			rear_single_tele_video_uhd60_mif = <5>;
			rear_single_tele_video_uhd60_int = <3>;
			rear_single_tele_video_uhd60_cpu = CPU_CL12;

			rear_single_tele_video_8k24_int_cam = <5>;
			rear_single_tele_video_8k24_cam = <5>;
			rear_single_tele_video_8k24_csis = <6>;
			rear_single_tele_video_8k24_isp = <5>;
			rear_single_tele_video_8k24_mif = <6>;
			rear_single_tele_video_8k24_int = <3>;
			rear_single_tele_video_8k24_cpu = CPU_CL0;

			rear_single_tele_video_8k24_hf_int_cam = <5>;
			rear_single_tele_video_8k24_hf_cam = <5>;
			rear_single_tele_video_8k24_hf_csis = <6>;
			rear_single_tele_video_8k24_hf_isp = <6>;
			rear_single_tele_video_8k24_hf_mif = <7>;
			rear_single_tele_video_8k24_hf_int = <3>;
			rear_single_tele_video_8k24_hf_cpu = CPU_CL0;

			rear_single_tele_video_8k30_int_cam = <4>;
			rear_single_tele_video_8k30_cam = <5>;
			rear_single_tele_video_8k30_csis = <6>;
			rear_single_tele_video_8k30_isp = <5>;
			rear_single_tele_video_8k30_mif = <4>;
			rear_single_tele_video_8k30_int = <2>;
			rear_single_tele_video_8k30_cpu = CPU_CL0;

			rear_single_tele_video_8k30_hf_int_cam = <4>;
			rear_single_tele_video_8k30_hf_cam = <5>;
			rear_single_tele_video_8k30_hf_csis = <6>;
			rear_single_tele_video_8k30_hf_isp = <6>;
			rear_single_tele_video_8k30_hf_mif = <5>;
			rear_single_tele_video_8k30_hf_int = <2>;
			rear_single_tele_video_8k30_hf_cpu = CPU_CL0;

			rear_single_tele_capture_int_cam = <3>;
			rear_single_tele_capture_cam = <3>;
			rear_single_tele_capture_csis = <6>;
			rear_single_tele_capture_isp = <3>;
			rear_single_tele_capture_mif = <1>;
			rear_single_tele_capture_int = <5>;
			rear_single_tele_capture_cpu = CPU_CL0;

			rear_single_tele_remosaic_photo_int_cam = <6>;
			rear_single_tele_remosaic_photo_cam = <6>;
			rear_single_tele_remosaic_photo_csis = <6>;
			rear_single_tele_remosaic_photo_isp = <6>;
			rear_single_tele_remosaic_photo_mif = <6>;
			rear_single_tele_remosaic_photo_int = <5>;
			rear_single_tele_remosaic_photo_cpu = CPU_CL0;

			rear_single_tele_remosaic_capture_int_cam = <3>;
			rear_single_tele_remosaic_capture_cam = <3>;
			rear_single_tele_remosaic_capture_csis = <6>;
			rear_single_tele_remosaic_capture_isp = <3>;
			rear_single_tele_remosaic_capture_mif = <1>;
			rear_single_tele_remosaic_capture_int = <5>;
			rear_single_tele_remosaic_capture_cpu = CPU_CL0;

			rear_dual_wide_tele_photo_int_cam = <6>;
			rear_dual_wide_tele_photo_cam = <1>;
			rear_dual_wide_tele_photo_csis = <5>;
			rear_dual_wide_tele_photo_isp = <1>;
			rear_dual_wide_tele_photo_mif = <6>;
			rear_dual_wide_tele_photo_int = <5>;
			rear_dual_wide_tele_photo_cpu = CPU_CL0;

			rear_dual_wide_tele_video_fhd30_int_cam = <6>;
			rear_dual_wide_tele_video_fhd30_cam = <1>;
			rear_dual_wide_tele_video_fhd30_csis = <5>;
			rear_dual_wide_tele_video_fhd30_isp = <1>;
			rear_dual_wide_tele_video_fhd30_mif = <6>;
			rear_dual_wide_tele_video_fhd30_int = <5>;
			rear_dual_wide_tele_video_fhd30_cpu = CPU_CL0;

			rear_dual_wide_tele_video_uhd30_int_cam = <6>;
			rear_dual_wide_tele_video_uhd30_cam = <1>;
			rear_dual_wide_tele_video_uhd30_csis = <5>;
			rear_dual_wide_tele_video_uhd30_isp = <1>;
			rear_dual_wide_tele_video_uhd30_mif = <5>;
			rear_dual_wide_tele_video_uhd30_int = <4>;
			rear_dual_wide_tele_video_uhd30_cpu = CPU_CL0;

			rear_dual_wide_tele_video_fhd60_int_cam = <6>;
			rear_dual_wide_tele_video_fhd60_cam = <1>;
			rear_dual_wide_tele_video_fhd60_csis = <5>;
			rear_dual_wide_tele_video_fhd60_isp = <1>;
			rear_dual_wide_tele_video_fhd60_mif = <5>;
			rear_dual_wide_tele_video_fhd60_int = <5>;
			rear_dual_wide_tele_video_fhd60_cpu = CPU_CL12;

			rear_dual_wide_tele_video_uhd60_int_cam = <1>;
			rear_dual_wide_tele_video_uhd60_cam = <1>;
			rear_dual_wide_tele_video_uhd60_csis = <1>;
			rear_dual_wide_tele_video_uhd60_isp = <1>;
			rear_dual_wide_tele_video_uhd60_mif = <1>;
			rear_dual_wide_tele_video_uhd60_int = <1>;
			rear_dual_wide_tele_video_uhd60_cpu = CPU_CL12;

			rear_dual_wide_tele_capture_int_cam = <3>;
			rear_dual_wide_tele_capture_cam = <1>;
			rear_dual_wide_tele_capture_csis = <5>;
			rear_dual_wide_tele_capture_isp = <1>;
			rear_dual_wide_tele_capture_mif = <1>;
			rear_dual_wide_tele_capture_int = <5>;
			rear_dual_wide_tele_capture_cpu = CPU_CL0;

			rear_dual_wide_ultrawide_photo_int_cam = <6>;
			rear_dual_wide_ultrawide_photo_cam = <1>;
			rear_dual_wide_ultrawide_photo_csis = <5>;
			rear_dual_wide_ultrawide_photo_isp = <1>;
			rear_dual_wide_ultrawide_photo_mif = <6>;
			rear_dual_wide_ultrawide_photo_int = <5>;
			rear_dual_wide_ultrawide_photo_cpu = CPU_CL0;

			rear_dual_wide_ultrawide_video_fhd30_int_cam = <6>;
			rear_dual_wide_ultrawide_video_fhd30_cam = <1>;
			rear_dual_wide_ultrawide_video_fhd30_csis = <5>;
			rear_dual_wide_ultrawide_video_fhd30_isp = <1>;
			rear_dual_wide_ultrawide_video_fhd30_mif = <6>;
			rear_dual_wide_ultrawide_video_fhd30_int = <5>;
			rear_dual_wide_ultrawide_video_fhd30_cpu = CPU_CL0;

			rear_dual_wide_ultrawide_video_uhd30_int_cam = <6>;
			rear_dual_wide_ultrawide_video_uhd30_cam = <1>;
			rear_dual_wide_ultrawide_video_uhd30_csis = <5>;
			rear_dual_wide_ultrawide_video_uhd30_isp = <1>;
			rear_dual_wide_ultrawide_video_uhd30_mif = <5>;
			rear_dual_wide_ultrawide_video_uhd30_int = <5>;
			rear_dual_wide_ultrawide_video_uhd30_cpu = CPU_CL0;

			rear_dual_wide_ultrawide_video_fhd60_int_cam = <6>;
			rear_dual_wide_ultrawide_video_fhd60_cam = <1>;
			rear_dual_wide_ultrawide_video_fhd60_csis = <5>;
			rear_dual_wide_ultrawide_video_fhd60_isp = <1>;
			rear_dual_wide_ultrawide_video_fhd60_mif = <5>;
			rear_dual_wide_ultrawide_video_fhd60_int = <5>;
			rear_dual_wide_ultrawide_video_fhd60_cpu = CPU_CL12;

			rear_dual_wide_ultrawide_video_uhd60_int_cam = <1>;
			rear_dual_wide_ultrawide_video_uhd60_cam = <1>;
			rear_dual_wide_ultrawide_video_uhd60_csis = <1>;
			rear_dual_wide_ultrawide_video_uhd60_isp = <1>;
			rear_dual_wide_ultrawide_video_uhd60_mif = <1>;
			rear_dual_wide_ultrawide_video_uhd60_int = <1>;
			rear_dual_wide_ultrawide_video_uhd60_cpu = CPU_CL12;

			rear_dual_wide_ultrawide_capture_int_cam = <3>;
			rear_dual_wide_ultrawide_capture_cam = <1>;
			rear_dual_wide_ultrawide_capture_csis = <5>;
			rear_dual_wide_ultrawide_capture_isp = <1>;
			rear_dual_wide_ultrawide_capture_mif = <1>;
			rear_dual_wide_ultrawide_capture_int = <5>;
			rear_dual_wide_ultrawide_capture_cpu = CPU_CL0;

			triple_photo_int_cam = <6>;
			triple_photo_cam = <1>;
			triple_photo_csis = <3>;
			triple_photo_isp = <1>;
			triple_photo_mif = <6>;
			triple_photo_int = <5>;
			triple_photo_cpu = CPU_CL0;

			triple_video_fhd30_int_cam = <6>;
			triple_video_fhd30_cam = <1>;
			triple_video_fhd30_csis = <3>;
			triple_video_fhd30_isp = <1>;
			triple_video_fhd30_mif = <6>;
			triple_video_fhd30_int = <5>;
			triple_video_fhd30_cpu = CPU_CL0;

			triple_video_uhd30_int_cam = <1>;
			triple_video_uhd30_cam = <1>;
			triple_video_uhd30_csis = <1>;
			triple_video_uhd30_isp = <1>;
			triple_video_uhd30_mif = <1>;
			triple_video_uhd30_int = <1>;
			triple_video_uhd30_cpu = CPU_CL0;

			triple_video_fhd60_int_cam = <6>;
			triple_video_fhd60_cam = <1>;
			triple_video_fhd60_csis = <3>;
			triple_video_fhd60_isp = <1>;
			triple_video_fhd60_mif = <5>;
			triple_video_fhd60_int = <5>;
			triple_video_fhd60_cpu = CPU_CL12;

			triple_video_uhd60_int_cam = <1>;
			triple_video_uhd60_cam = <1>;
			triple_video_uhd60_csis = <1>;
			triple_video_uhd60_isp = <1>;
			triple_video_uhd60_mif = <1>;
			triple_video_uhd60_int = <1>;
			triple_video_uhd60_cpu = CPU_CL12;

			triple_capture_int_cam = <3>;
			triple_capture_cam = <1>;
			triple_capture_csis = <3>;
			triple_capture_isp = <1>;
			triple_capture_mif = <1>;
			triple_capture_int = <5>;
			triple_capture_cpu = CPU_CL0;

			front_single_photo_int_cam = <6>;
			front_single_photo_cam = <6>;
			front_single_photo_csis = <6>;
			front_single_photo_isp = <6>;
			front_single_photo_mif = <6>;
			front_single_photo_int = <5>;
			front_single_photo_cpu = CPU_CL0;

			front_single_photo_full_int_cam = <6>;
			front_single_photo_full_cam = <6>;
			front_single_photo_full_csis = <6>;
			front_single_photo_full_isp = <6>;
			front_single_photo_full_mif = <3>;
			front_single_photo_full_int = <5>;
			front_single_photo_full_cpu = CPU_CL0;

			front_single_video_fhd30_int_cam = <6>;
			front_single_video_fhd30_cam = <7>;
			front_single_video_fhd30_csis = <6>;
			front_single_video_fhd30_isp = <7>;
			front_single_video_fhd30_mif = <8>;
			front_single_video_fhd30_int = <5>;
			front_single_video_fhd30_cpu = CPU_CL0;

			front_single_video_uhd30_int_cam = <6>;
			front_single_video_uhd30_cam = <6>;
			front_single_video_uhd30_csis = <6>;
			front_single_video_uhd30_isp = <7>;
			front_single_video_uhd30_mif = <7>;
			front_single_video_uhd30_int = <4>;
			front_single_video_uhd30_cpu = CPU_CL0;

			front_single_video_fhd60_int_cam = <6>;
			front_single_video_fhd60_cam = <6>;
			front_single_video_fhd60_csis = <6>;
			front_single_video_fhd60_isp = <6>;
			front_single_video_fhd60_mif = <7>;
			front_single_video_fhd60_int = <5>;
			front_single_video_fhd60_cpu = CPU_CL12;

			front_single_video_uhd60_int_cam = <5>;
			front_single_video_uhd60_cam = <5>;
			front_single_video_uhd60_csis = <6>;
			front_single_video_uhd60_isp = <6>;
			front_single_video_uhd60_mif = <5>;
			front_single_video_uhd60_int = <3>;
			front_single_video_uhd60_cpu = CPU_CL12;

			front_single_video_uhd120_int_cam = <6>;
			front_single_video_uhd120_cam = <4>;
			front_single_video_uhd120_csis = <6>;
			front_single_video_uhd120_isp = <4>;
			front_single_video_uhd120_mif = <3>;
			front_single_video_uhd120_int = <2>;
			front_single_video_uhd120_cpu = CPU_CL12;

			front_single_capture_int_cam = <3>;
			front_single_capture_cam = <3>;
			front_single_capture_csis = <6>;
			front_single_capture_isp = <3>;
			front_single_capture_mif = <1>;
			front_single_capture_int = <5>;
			front_single_capture_cpu = CPU_CL0;

			front_single_vt_int_cam = <6>;
			front_single_vt_cam = <7>;
			front_single_vt_csis = <6>;
			front_single_vt_isp = <7>;
			front_single_vt_mif = <8>;
			front_single_vt_int = <5>;
			front_single_vt_cpu = CPU_CL0;

			front_single_video_fhd120_int_cam = <6>;
			front_single_video_fhd120_cam = <5>;
			front_single_video_fhd120_csis = <6>;
			front_single_video_fhd120_isp = <7>;
			front_single_video_fhd120_mif = <5>;
			front_single_video_fhd120_int = <4>;
			front_single_video_fhd120_hpg = <8>;
			front_single_video_fhd120_cpu = CPU_CL12;

			rear_single_wide_fastae_int_cam = <1>;
			rear_single_wide_fastae_cam = <1>;            /* VOTF */
			rear_single_wide_fastae_csis = <1>;  /* VOTF */
			rear_single_wide_fastae_isp = <1>;
			rear_single_wide_fastae_mif = <1>;
			rear_single_wide_fastae_int = <1>;
			rear_single_wide_fastae_cpu = CPU_CL0;

			front_single_fastae_int_cam = <1>;
			front_single_fastae_cam = <1>;
			front_single_fastae_csis = <1>;
			front_single_fastae_isp = <1>;
			front_single_fastae_mif = <1>;
			front_single_fastae_int = <1>;
			front_single_fastae_cpu = CPU_CL0;

			pip_dual_photo_int_cam = <6>;
			pip_dual_photo_cam = <5>;
			pip_dual_photo_csis = <5>;
			pip_dual_photo_isp = <7>;
			pip_dual_photo_mif = <6>;
			pip_dual_photo_int = <6>;
			pip_dual_photo_cpu = CPU_CL0;

			pip_dual_capture_int_cam = <3>;
			pip_dual_capture_cam = <1>;
			pip_dual_capture_csis = <5>;
			pip_dual_capture_isp = <1>;
			pip_dual_capture_mif = <1>;
			pip_dual_capture_int = <1>;
			pip_dual_capture_cpu = CPU_CL0;

			pip_dual_video_fhd30_int_cam = <6>;
			pip_dual_video_fhd30_cam = <5>;
			pip_dual_video_fhd30_csis = <5>;
			pip_dual_video_fhd30_isp = <7>;
			pip_dual_video_fhd30_mif = <6>;
			pip_dual_video_fhd30_int = <6>;
			pip_dual_video_fhd30_cpu = CPU_CL0;

			ext_rear_single_int_cam = <1>;
			ext_rear_single_cam = <1>;
			ext_rear_single_csis = <1>;
			ext_rear_single_isp = <1>;
			ext_rear_single_mif = <1>;
			ext_rear_single_int = <1>;
			ext_rear_single_cpu = CPU_CL0;

			ext_front_secure_int_cam = <1>;
			ext_front_secure_cam = <1>;
			ext_front_secure_csis = <1>;
			ext_front_secure_isp = <1>;
			ext_front_secure_mif = <1>;
			ext_front_secure_int = <1>;
			ext_front_secure_cpu = CPU_CL0;

			ext_throttling_int_cam = <6>;
			ext_throttling_cam = <0>;
			ext_throttling_csis = <0>;
			ext_throttling_isp = <0>;
			ext_throttling_mif = <6>;
			ext_throttling_int = <0>;
			ext_throttling_hpg = <0>;
			ext_throttling_cpu = CPU_CL0;

			max_int_cam = <1>;
			max_cam = <1>;
			max_csis = <1>;
			max_isp = <1>;
			max_mif = <1>;
			max_int = <1>;
			max_cpu = CPU_CL0;
		};
	};

	/*
	 * default setfiles for CPHY
	 * <addr, bit_start, bit_width, val, index, max_lane>
	 */
	cphy_setfile: cphy-setfile@00 {
		comm {
		       /* bias */
		       0  = <0x1000 0 32 0x00000010 IDX_BIA_VAL 0>; /* M_BIAS_CON0 */
		       1  = <0x1004 0 32 0x00000110 IDX_BIA_VAL 0>; /* M_BIAS_CON1 */
		       2  = <0x1008 0 32 0x00003223 IDX_BIA_VAL 0>; /* M_BIAS_CON2 */
		       3  = <0x1010 0 32 0x00000240 IDX_BIA_VAL 0>; /* M_BIAS_CON4 */
		       4  = <0x1114 0 32 0x00000500 IDX_BIA_VAL 0>; /* M_PLL_CON5 */
		       5  = <0x1118 0 32 0x00000010 IDX_BIA_VAL 0>; /* M_PLL_CON6 */
		       6  = <0x111C 0 32 0x00003D40 IDX_BIA_VAL 0>; /* M_PLL_CON7 */
		       7  = <0x1120 0 32 0x00001E00 IDX_BIA_VAL 0>; /* M_PLL_CON8 */
		       8  = <0x1124 0 32 0x00001300 IDX_BIA_VAL 0>; /* M_PLL_CON9 */
		};

		lane {
			0  = <0x0004 0 32 0x00003D40 IDX_FIX_VAL 3>; /* SD_GNR_CON1 */
			1  = <0x0008 0 32 0x00000031 IDX_FIX_VAL 3>; /* SD_ANA_CON0 */
			2  = <0x000C 0 32 0x0000B349 IDX_FIX_VAL 3>; /* SD_ANA_CON1 */
			3  = <0x0010 0 32 0x00000005 IDX_FIX_VAL 3>; /* SD_ANA_CON2 */
			4  = <0x0014 0 32 0x00008600 IDX_FIX_VAL 3>; /* SD_ANA_CON3 */
			5  = <0x0018 0 32 0x00004040 IDX_FIX_VAL 3>; /* SD_ANA_CON4 */
			6  = <0x001C 0 32 0x00002200 IDX_FIX_VAL 3>; /* SD_ANA_CON5 */
			7  = <0x0020 0 32 0x00000E08 IDX_FIX_VAL 3>; /* SD_ANA_CON6 */
			8  = <0x0024 0 32 0x00000040 IDX_FIX_VAL 3>; /* SD_ANA_CON7 */
			9  = <0x0030 0  8 0x00000000 IDX_STL_VAL 3>; /* SD_TIME_CON0 */
			10 = <0x0030 8  1 0x00000000 IDX_STL_CLK 3>; /* SD_TIME_CON0 */
			11 = <0x0034 0 32 0x00000034 IDX_FIX_VAL 3>; /* SD_TIME_CON1 */
			12 = <0x005C 0 32 0x00001000 IDX_FIX_VAL 3>; /* SD_CRC_DLY_CON0 */
			13 = <0x0064 0 32 0x00001501 IDX_FIX_VAL 3>; /* SD_CRC_CON1 */
			14 = <0x0068 0 32 0x00000023 IDX_FIX_VAL 3>; /* SD_CRC_CON2 */
			15 = <0x009c 0 32 0x00000080 IDX_FIX_VAL 3>; /* SD_CRC_DLY_CON3 */

			/* Enable should be set at last */
			16 = <0x0000 0 32 0x00000001 IDX_FIX_VAL 3>; /* SD_GNR_CON0 */
		};
	};

	cphy_gn3_setfile: cphy-gn3-setfile@00 {
		comm {
		       /* bias */
		       0  = <0x1000 0 32 0x00000010 IDX_BIA_VAL 0>; /* M_BIAS_CON0 */
		       1  = <0x1004 0 32 0x00000110 IDX_BIA_VAL 0>; /* M_BIAS_CON1 */
		       2  = <0x1008 0 32 0x00003223 IDX_BIA_VAL 0>; /* M_BIAS_CON2 */
		       3  = <0x1010 0 32 0x00000240 IDX_BIA_VAL 0>; /* M_BIAS_CON4 */
		       4  = <0x1114 0 32 0x00000500 IDX_BIA_VAL 0>; /* M_PLL_CON5 */
		       5  = <0x1118 0 32 0x00000010 IDX_BIA_VAL 0>; /* M_PLL_CON6 */
		       6  = <0x111C 0 32 0x00003D40 IDX_BIA_VAL 0>; /* M_PLL_CON7 */
		       7  = <0x1120 0 32 0x00001E00 IDX_BIA_VAL 0>; /* M_PLL_CON8 */
		       8  = <0x1124 0 32 0x00001300 IDX_BIA_VAL 0>; /* M_PLL_CON9 */
		};

		lane {
			0  = <0x0004 0 32 0x00003D40 IDX_FIX_VAL 3>; /* SD_GNR_CON1 */
			1  = <0x0008 0 32 0x000000F3 IDX_FIX_VAL 3>; /* SD_ANA_CON0 */
			2  = <0x000C 0 32 0x0000B749 IDX_FIX_VAL 3>; /* SD_ANA_CON1 */
			3  = <0x0010 0 32 0x00000000 IDX_FIX_VAL 3>; /* SD_ANA_CON2 */
			4  = <0x0014 0 32 0x00008600 IDX_FIX_VAL 3>; /* SD_ANA_CON3 */
			5  = <0x0018 0 32 0x00004040 IDX_FIX_VAL 3>; /* SD_ANA_CON4 */
			6  = <0x001C 0 32 0x00002200 IDX_FIX_VAL 3>; /* SD_ANA_CON5 */
			7  = <0x0020 0 32 0x00000E08 IDX_FIX_VAL 3>; /* SD_ANA_CON6 */
			8  = <0x0024 0 32 0x00000040 IDX_FIX_VAL 3>; /* SD_ANA_CON7 */
			9  = <0x0030 0  8 0x00000000 IDX_STL_VAL 3>; /* SD_TIME_CON0 */
			10 = <0x0030 8  1 0x00000000 IDX_STL_CLK 3>; /* SD_TIME_CON0 */
			11 = <0x0034 0 32 0x00000034 IDX_FIX_VAL 3>; /* SD_TIME_CON1 */
			12 = <0x005C 0 32 0x00001000 IDX_FIX_VAL 3>; /* SD_CRC_DLY_CON0 */
			13 = <0x0064 0 32 0x00001501 IDX_FIX_VAL 3>; /* SD_CRC_CON1 */
			14 = <0x0068 0 32 0x00000023 IDX_FIX_VAL 3>; /* SD_CRC_CON2 */
			15 = <0x009c 0 32 0x00000080 IDX_FIX_VAL 3>; /* SD_CRC_DLY_CON3 */

			/* Enable should be set at last */
			16 = <0x0000 0 32 0x00000001 IDX_FIX_VAL 3>; /* SD_GNR_CON0 */
		};
	};

	cphy_2la_setfile: cphy-2la-setfile@00 {
		comm {
		       /* bias */
		       0  = <0x1000 0 32 0x00000010 IDX_BIA_VAL 0>; /* M_BIAS_CON0 */
		       1  = <0x1004 0 32 0x00000110 IDX_BIA_VAL 0>; /* M_BIAS_CON1 */
		       2  = <0x1008 0 32 0x00003223 IDX_BIA_VAL 0>; /* M_BIAS_CON2 */
		       3  = <0x1010 0 32 0x00000240 IDX_BIA_VAL 0>; /* M_BIAS_CON4 */
		       4  = <0x1114 0 32 0x00000500 IDX_BIA_VAL 0>; /* M_PLL_CON5 */
		       5  = <0x1118 0 32 0x00000010 IDX_BIA_VAL 0>; /* M_PLL_CON6 */
		       6  = <0x111C 0 32 0x00003D40 IDX_BIA_VAL 0>; /* M_PLL_CON7 */
		       7  = <0x1120 0 32 0x00001E00 IDX_BIA_VAL 0>; /* M_PLL_CON8 */
		       8  = <0x1124 0 32 0x00001300 IDX_BIA_VAL 0>; /* M_PLL_CON9 */
		};

		lane {
			0  = <0x0004 0 32 0x00003D40 IDX_FIX_VAL 3>; /* SD_GNR_CON1 */
			1  = <0x0008 0 32 0x00000011 IDX_FIX_VAL 3>; /* SD_ANA_CON0 */
			2  = <0x000C 0 32 0x00009321 IDX_FIX_VAL 3>; /* SD_ANA_CON1 */
			3  = <0x0010 0 32 0x00000003 IDX_FIX_VAL 3>; /* SD_ANA_CON2 */
			4  = <0x0014 0 32 0x00008600 IDX_FIX_VAL 3>; /* SD_ANA_CON3 */
			5  = <0x0018 0 32 0x00004040 IDX_FIX_VAL 3>; /* SD_ANA_CON4 */
			6  = <0x001C 0 32 0x00002200 IDX_FIX_VAL 3>; /* SD_ANA_CON5 */
			7  = <0x0020 0 32 0x00000E08 IDX_FIX_VAL 3>; /* SD_ANA_CON6 */
			8  = <0x0024 0 32 0x00000040 IDX_FIX_VAL 3>; /* SD_ANA_CON7 */
			9  = <0x0030 0  8 0x00000000 IDX_STL_VAL 3>; /* SD_TIME_CON0 */
			10 = <0x0030 8  1 0x00000000 IDX_STL_CLK 3>; /* SD_TIME_CON0 */
			11 = <0x0034 0 32 0x00000034 IDX_FIX_VAL 3>; /* SD_TIME_CON1 */
			12 = <0x005C 0 32 0x00001000 IDX_FIX_VAL 3>; /* SD_CRC_DLY_CON0 */
			13 = <0x0064 0 32 0x00001501 IDX_FIX_VAL 3>; /* SD_CRC_CON1 */
			14 = <0x0068 0 32 0x00000023 IDX_FIX_VAL 3>; /* SD_CRC_CON2 */
			15 = <0x009c 0 32 0x00000080 IDX_FIX_VAL 3>; /* SD_CRC_DLY_CON3 */

			/* Enable should be set at last */
			16 = <0x0000 0 32 0x00000001 IDX_FIX_VAL 3>; /* SD_GNR_CON0 */
		};
	};
};
